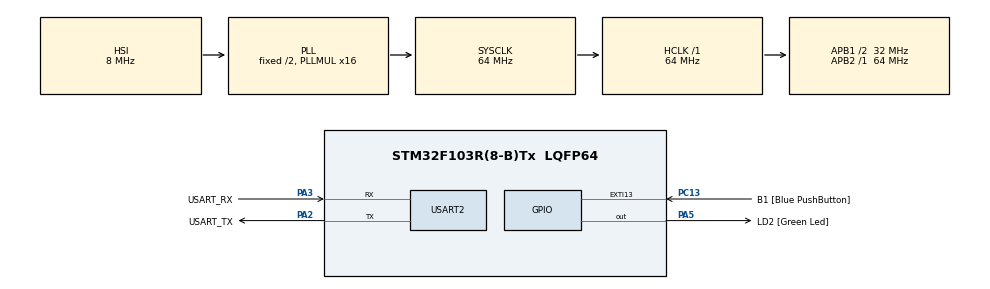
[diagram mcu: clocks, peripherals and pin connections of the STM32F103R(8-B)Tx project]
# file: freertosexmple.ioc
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Dma.Request0=USART2_RX
Dma.Request1=USART2_TX
Dma.USART2_RX.0.Direction=DMA_PERIPH_TO_MEMORY
Dma.USART2_RX.0.Instance=DMA1_Channel6
Dma.USART2_RX.0.MemDataAlignment=DMA_MDATAALIGN_BYTE
Dma.USART2_RX.0.MemInc=DMA_MINC_ENABLE
Dma.USART2_RX.0.Mode=DMA_NORMAL
Dma.USART2_RX.0.PeriphDataAlignment=DMA_PDATAALIGN_BYTE
Dma.USART2_RX.0.PeriphInc=DMA_PINC_DISABLE
Dma.USART2_RX.0.Priority=DMA_PRIORITY_LOW
Dma.USART2_TX.1.Direction=DMA_MEMORY_TO_PERIPH
Dma.USART2_TX.1.Instance=DMA1_Channel7
Dma.USART2_TX.1.MemDataAlignment=DMA_MDATAALIGN_BYTE
Dma.USART2_TX.1.MemInc=DMA_MINC_ENABLE
Dma.USART2_TX.1.Mode=DMA_NORMAL
Dma.USART2_TX.1.PeriphDataAlignment=DMA_PDATAALIGN_BYTE
Dma.USART2_TX.1.PeriphInc=DMA_PINC_DISABLE
Dma.USART2_TX.1.Priority=DMA_PRIORITY_LOW
FREERTOS.Tasks01=defaultTask,0,128,StartDefaultTask,Default,NULL,Dynamic,NULL,NULL;myTask02,-3,128,StartTask02,Default,NULL,Dynamic,NULL,NULL
Mcu.Family=STM32F1
Mcu.Name=STM32F103R(8-B)Tx
Mcu.Package=LQFP64
NVIC.DMA1_Channel6_IRQn=true\:5\:0\:false\:false\:true\:true\:false
NVIC.DMA1_Channel7_IRQn=true\:5\:0\:false\:false\:true\:true\:false
NVIC.EXTI15_10_IRQn=true\:5\:0\:false\:false\:true\:true\:true
NVIC.PriorityGroup=NVIC_PRIORITYGROUP_4
PA13.GPIO_Label=TMS
PA13.Mode=Serial_Wire
PA13.Signal=SYS_JTMS-SWDIO
PA14.GPIO_Label=TCK
PA14.Mode=Serial_Wire
PA14.Signal=SYS_JTCK-SWCLK
PA2.GPIO_Label=USART_TX
PA2.GPIO_Mode=GPIO_MODE_AF_PP
PA2.GPIO_PuPd=GPIO_NOPULL
PA2.GPIO_Speed=GPIO_SPEED_FREQ_LOW
PA2.Mode=Asynchronous
PA2.Signal=USART2_TX
PA3.GPIO_Label=USART_RX
PA3.GPIO_Mode=GPIO_MODE_AF_PP
PA3.GPIO_PuPd=GPIO_NOPULL
PA3.GPIO_Speed=GPIO_SPEED_FREQ_LOW
PA3.Mode=Asynchronous
PA3.Signal=USART2_RX
PA5.GPIO_Label=LD2 [Green Led]
PA5.GPIO_ModeDefaultOutputPP=GPIO_MODE_OUTPUT_PP
PA5.GPIO_PuPd=GPIO_NOPULL
PA5.GPIO_Speed=GPIO_SPEED_FREQ_LOW
PA5.Signal=GPIO_Output
PB3.GPIO_Label=SWO
PB3.Signal=SYS_JTDO-TRACESWO
PC13-TAMPER-RTC.GPIO_Label=B1 [Blue PushButton]
PC13-TAMPER-RTC.GPIO_PuPd=GPIO_NOPULL
PC13-TAMPER-RTC.Signal=GPXTI13
PC14-OSC32_IN.Mode=LSE-External-Oscillator
PC14-OSC32_IN.Signal=RCC_OSC32_IN
PC15-OSC32_OUT.Mode=LSE-External-Oscillator
PC15-OSC32_OUT.Signal=RCC_OSC32_OUT
PD0-OSC_IN.Mode=HSE-External-Clock-Source
PD0-OSC_IN.Signal=RCC_OSC_IN
PD1-OSC_OUT.Mode=HSE-External-Clock-Source
PD1-OSC_OUT.Signal=RCC_OSC_OUT
ProjectManager.HeapSize=0x200
ProjectManager.StackSize=0x400
ProjectManager.TargetToolchain=SW4STM32
RCC.AHBFreq_Value=64000000
RCC.APB1CLKDivider=RCC_HCLK_DIV2
RCC.APB1Freq_Value=32000000
RCC.APB1TimFreq_Value=64000000
RCC.APB2Freq_Value=64000000
RCC.APB2TimFreq_Value=64000000
RCC.HCLKFreq_Value=64000000
RCC.PLLMUL=RCC_PLL_MUL16
RCC.RTCClockSelection=RCC_RTCCLKSOURCE_LSE
RCC.SYSCLKFreq_VALUE=64000000
RCC.SYSCLKSource=RCC_SYSCLKSOURCE_PLLCLK
RCC.USBFreq_Value=64000000
USART2.VirtualMode=VM_ASYNC
VP_FREERTOS_VS_ENABLE.Mode=Enabled
board=NUCLEO-F103RB

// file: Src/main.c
/**
  ******************************************************************************
  * @file           : main.c
  * @brief          : Main program body
  ******************************************************************************
  * This notice applies to any and all portions of this file
  * that are not between comment pairs USER CODE BEGIN and
  * USER CODE END. Other portions of this file, whether
  * inserted by the user or by software development tools
  * are owned by their respective copyright owners.
  *
  * Copyright (c) 2022 STMicroelectronics International N.V.
  * All rights reserved.
  *
  * Redistribution and use in source and binary forms, with or without
  * modification, are permitted, provided that the following conditions are met:
  *
  * 1. Redistribution of source code must retain the above copyright notice,
  *    this list of conditions and the following disclaimer.
  * 2. Redistributions in binary form must reproduce the above copyright notice,
  *    this list of conditions and the following disclaimer in the documentation
  *    and/or other materials provided with the distribution.
  * 3. Neither the name of STMicroelectronics nor the names of other
  *    contributors to this software may be used to endorse or promote products
  *    derived from this software without specific written permission.
  * 4. This software, including modifications and/or derivative works of this
  *    software, must execute solely and exclusively on microcontroller or
  *    microprocessor devices manufactured by or for STMicroelectronics.
  * 5. Redistribution and use of this software other than as permitted under
  *    this license is void and will automatically terminate your rights under
  *    this license.
  *
  * THIS SOFTWARE IS PROVIDED BY STMICROELECTRONICS AND CONTRIBUTORS "AS IS"
  * AND ANY EXPRESS, IMPLIED OR STATUTORY WARRANTIES, INCLUDING, BUT NOT
  * LIMITED TO, THE IMPLIED WARRANTIES OF MERCHANTABILITY, FITNESS FOR A
  * PARTICULAR PURPOSE AND NON-INFRINGEMENT OF THIRD PARTY INTELLECTUAL PROPERTY
  * RIGHTS ARE DISCLAIMED TO THE FULLEST EXTENT PERMITTED BY LAW. IN NO EVENT
  * SHALL STMICROELECTRONICS OR CONTRIBUTORS BE LIABLE FOR ANY DIRECT, INDIRECT,
  * INCIDENTAL, SPECIAL, EXEMPLARY, OR CONSEQUENTIAL DAMAGES (INCLUDING, BUT NOT
  * LIMITED TO, PROCUREMENT OF SUBSTITUTE GOODS OR SERVICES; LOSS OF USE, DATA,
  * OR PROFITS; OR BUSINESS INTERRUPTION) HOWEVER CAUSED AND ON ANY THEORY OF
  * LIABILITY, WHETHER IN CONTRACT, STRICT LIABILITY, OR TORT (INCLUDING
  * NEGLIGENCE OR OTHERWISE) ARISING IN ANY WAY OUT OF THE USE OF THIS SOFTWARE,
  * EVEN IF ADVISED OF THE POSSIBILITY OF SUCH DAMAGE.
  *
  ******************************************************************************
  */
#include "main.h"
#include "stm32f1xx_hal.h"
#include "cmsis_os.h"

UART_HandleTypeDef huart2;
DMA_HandleTypeDef hdma_usart2_rx;
DMA_HandleTypeDef hdma_usart2_tx;

osThreadId defaultTaskHandle;
osThreadId myTask02Handle;

/* USER CODE BEGIN PV */
/* Private variables ---------------------------------------------------------*/

/* USER CODE END PV */

void SystemClock_Config(void);
static void MX_GPIO_Init(void);
static void MX_DMA_Init(void);
static void MX_USART2_UART_Init(void);
void StartDefaultTask(void const * argument);
void StartTask02(void const * argument);

/* USER CODE BEGIN PFP */
/* Private function prototypes -----------------------------------------------*/

/* USER CODE END PFP */

int main(void)
{

  /* MCU Configuration----------------------------------------------------------*/

  /* Reset of all peripherals, Initializes the Flash interface and the Systick. */
  HAL_Init();

  /* Configure the system clock */
  SystemClock_Config();

  /* Initialize all configured peripherals */
  MX_GPIO_Init();
  MX_DMA_Init();
  MX_USART2_UART_Init();

  /* Create the thread(s) */
  /* definition and creation of defaultTask */
  osThreadDef(defaultTask, StartDefaultTask, osPriorityNormal, 0, 128);
  defaultTaskHandle = osThreadCreate(osThread(defaultTask), NULL);

  /* definition and creation of myTask02 */
  osThreadDef(myTask02, StartTask02, osPriorityIdle, 0, 128);
  myTask02Handle = osThreadCreate(osThread(myTask02), NULL);

  /* Start scheduler */
  osKernelStart();

  /* We should never get here as control is now taken by the scheduler */

  /* Infinite loop */
  while (1)
  {

  }

}

void SystemClock_Config(void)
{

  RCC_OscInitTypeDef RCC_OscInitStruct;
  RCC_ClkInitTypeDef RCC_ClkInitStruct;

    /**Initializes the CPU, AHB and APB busses clocks
    */
  RCC_OscInitStruct.OscillatorType = RCC_OSCILLATORTYPE_HSI;
  RCC_OscInitStruct.HSIState = RCC_HSI_ON;
  RCC_OscInitStruct.HSICalibrationValue = 16;
  RCC_OscInitStruct.PLL.PLLState = RCC_PLL_ON;
  RCC_OscInitStruct.PLL.PLLSource = RCC_PLLSOURCE_HSI_DIV2;
  RCC_OscInitStruct.PLL.PLLMUL = RCC_PLL_MUL16;
  if (HAL_RCC_OscConfig(&RCC_OscInitStruct) != HAL_OK)
  {
    _Error_Handler(__FILE__, __LINE__);
  }

    /**Initializes the CPU, AHB and APB busses clocks
    */
  RCC_ClkInitStruct.ClockType = RCC_CLOCKTYPE_HCLK|RCC_CLOCKTYPE_SYSCLK
                              |RCC_CLOCKTYPE_PCLK1|RCC_CLOCKTYPE_PCLK2;
  RCC_ClkInitStruct.SYSCLKSource = RCC_SYSCLKSOURCE_PLLCLK;
  RCC_ClkInitStruct.AHBCLKDivider = RCC_SYSCLK_DIV1;
  RCC_ClkInitStruct.APB1CLKDivider = RCC_HCLK_DIV2;
  RCC_ClkInitStruct.APB2CLKDivider = RCC_HCLK_DIV1;

  if (HAL_RCC_ClockConfig(&RCC_ClkInitStruct, FLASH_LATENCY_2) != HAL_OK)
  {
    _Error_Handler(__FILE__, __LINE__);
  }

    /**Configure the Systick interrupt time
    */
  HAL_SYSTICK_Config(HAL_RCC_GetHCLKFreq()/1000);

    /**Configure the Systick
    */
  HAL_SYSTICK_CLKSourceConfig(SYSTICK_CLKSOURCE_HCLK);

  /* SysTick_IRQn interrupt configuration */
  HAL_NVIC_SetPriority(SysTick_IRQn, 15, 0);
}

/* USART2 init function */
static void MX_USART2_UART_Init(void)
{

  huart2.Instance = USART2;
  huart2.Init.BaudRate = 115200;
  huart2.Init.WordLength = UART_WORDLENGTH_8B;
  huart2.Init.StopBits = UART_STOPBITS_1;
  huart2.Init.Parity = UART_PARITY_NONE;
  huart2.Init.Mode = UART_MODE_TX_RX;
  huart2.Init.HwFlowCtl = UART_HWCONTROL_NONE;
  huart2.Init.OverSampling = UART_OVERSAMPLING_16;
  if (HAL_UART_Init(&huart2) != HAL_OK)
  {
    _Error_Handler(__FILE__, __LINE__);
  }

}

static void MX_DMA_Init(void)
{
  /* DMA controller clock enable */
  __HAL_RCC_DMA1_CLK_ENABLE();

  /* DMA interrupt init */
  /* DMA1_Channel6_IRQn interrupt configuration */
  HAL_NVIC_SetPriority(DMA1_Channel6_IRQn, 5, 0);
  HAL_NVIC_EnableIRQ(DMA1_Channel6_IRQn);
  /* DMA1_Channel7_IRQn interrupt configuration */
  HAL_NVIC_SetPriority(DMA1_Channel7_IRQn, 5, 0);
  HAL_NVIC_EnableIRQ(DMA1_Channel7_IRQn);

}

/** Configure pins as
        * Analog
        * Input
        * Output
        * EVENT_OUT
        * EXTI
*/
static void MX_GPIO_Init(void)
{

  GPIO_InitTypeDef GPIO_InitStruct;

  /* GPIO Ports Clock Enable */
  __HAL_RCC_GPIOC_CLK_ENABLE();
  __HAL_RCC_GPIOD_CLK_ENABLE();
  __HAL_RCC_GPIOA_CLK_ENABLE();
  __HAL_RCC_GPIOB_CLK_ENABLE();

  /*Configure GPIO pin Output Level */
  HAL_GPIO_WritePin(LD2_GPIO_Port, LD2_Pin, GPIO_PIN_RESET);

  /*Configure GPIO pin : B1_Pin */
  GPIO_InitStruct.Pin = B1_Pin;
  GPIO_InitStruct.Mode = GPIO_MODE_IT_RISING;
  GPIO_InitStruct.Pull = GPIO_NOPULL;
  HAL_GPIO_Init(B1_GPIO_Port, &GPIO_InitStruct);

  /*Configure GPIO pin : LD2_Pin */
  GPIO_InitStruct.Pin = LD2_Pin;
  GPIO_InitStruct.Mode = GPIO_MODE_OUTPUT_PP;
  GPIO_InitStruct.Pull = GPIO_NOPULL;
  GPIO_InitStruct.Speed = GPIO_SPEED_FREQ_LOW;
  HAL_GPIO_Init(LD2_GPIO_Port, &GPIO_InitStruct);

  /* EXTI interrupt init*/
  HAL_NVIC_SetPriority(EXTI15_10_IRQn, 5, 0);
  HAL_NVIC_EnableIRQ(EXTI15_10_IRQn);

}

void StartDefaultTask(void const * argument)
{

  /* USER CODE BEGIN 5 */
	uint8_t rx[100];
  /* Infinite loop */
  for(;;)
  {
	  HAL_UART_Receive(&huart2,rx,25,100);
    osDelay(10);
  }
  /* USER CODE END 5 */
}

void StartTask02(void const * argument)
{
  /* USER CODE BEGIN StartTask02 */
  /* Infinite loop */
  for(;;)
  {
	  HAL_UART_Transmit(&huart2,"**kranthi**",13,100);
    osDelay(1);
  }
  /* USER CODE END StartTask02 */
}

void _Error_Handler(char *file, int line)
{
  while(1)
  {
  }
}

/************************ (C) COPYRIGHT STMicroelectronics *****END OF FILE****/
